# XHCI register map
File version: 1.2
xHCI host controller
Registers are read-write, no defined reset value unless marked. A register's access mark holds for its fields unless they carry their own. Offsets are from the block's base; lines under a group give offsets from that group; [hi:lo] are bit positions; {n}, {i} and the like mark numbered series; 'fields as' and 'values as' point back to an identical list; <NAME> marks a mode.

## Memory map
0x00000000 XHCI size 0x20

## XHCI
Base 0x00000000
0x00 CAPABILITY group
  0x00 CAPLENGTH 8-bit ro
  0x02 HCIVERSION 16-bit ro
    [15:0] VERSION
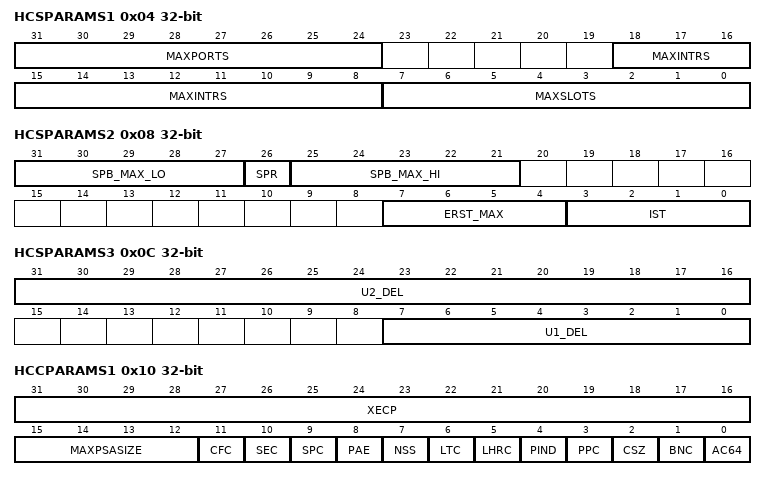
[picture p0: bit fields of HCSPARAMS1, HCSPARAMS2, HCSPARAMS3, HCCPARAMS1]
  0x04 HCSPARAMS1 ro
    [31:24] MAXPORTS, [18:8] MAXINTRS, [7:0] MAXSLOTS
  0x08 HCSPARAMS2 ro
    [31:27] SPB_MAX_LO, [26] SPR, [25:21] SPB_MAX_HI, [7:4] ERST_MAX, [3:0] IST
  0x0C HCSPARAMS3 ro
    [31:16] U2_DEL, [7:0] U1_DEL
  0x10 HCCPARAMS1 ro
    [31:16] XECP, [15:12] MAXPSASIZE, [11] CFC, [10] SEC, [9] SPC, [8] PAE, [7] NSS, [6] LTC, [5] LHRC, [4] PIND, [3] PPC, [2] CSZ, [1] BNC, [0] AC64
  0x14 DBOFF ro
    [31:2] OFFSET
  0x18 RTSOFF ro
    [31:5] OFFSET
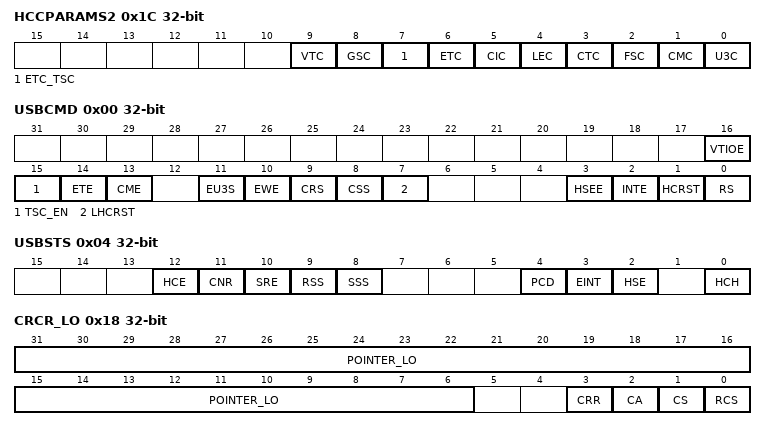
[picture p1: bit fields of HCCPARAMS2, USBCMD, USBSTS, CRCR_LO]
  0x1C HCCPARAMS2 ro
    [9] VTC, [8] GSC, [7] ETC_TSC, [6] ETC, [5] CIC, [4] LEC, [3] CTC, [2] FSC, [1] CMC, [0] U3C
0x00 OPERATIONAL group
  0x00 USBCMD
    [16] VTIOE, [15] TSC_EN, [14] ETE, [13] CME, [11] EU3S, [10] EWE, [9] CRS wo, [8] CSS wo, [7] LHCRST write-1-sets, [3] HSEE, [2] INTE, [1] HCRST write-1-sets, [0] RS
  0x04 USBSTS
    [12] HCE ro, [11] CNR ro, [10] SRE write-1-clears, [9] RSS ro, [8] SSS ro, [4] PCD write-1-clears, [3] EINT write-1-clears, [2] HSE write-1-clears, [0] HCH ro
  0x08 PAGESIZE ro
    [0] FOUR_KIB
  0x18 CRCR_LO
    [31:6] POINTER_LO wo, [3] CRR ro, [2] CA wo write-1-sets, [1] CS wo write-1-sets, [0] RCS wo
  0x1C CRCR_HI wo
    [31:0] POINTER_HI
  0x30 DCBAAP_LO
    [31:6] POINTER_LO
  0x34 DCBAAP_HI
    [31:0] POINTER_HI
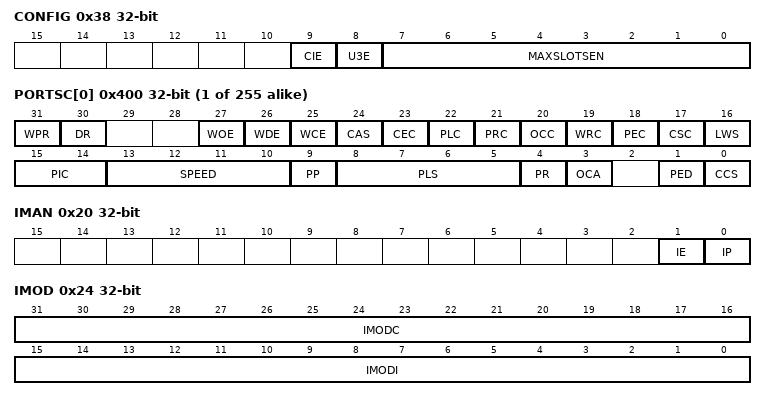
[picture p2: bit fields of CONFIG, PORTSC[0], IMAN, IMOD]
  0x38 CONFIG
    [9] CIE, [8] U3E, [7:0] MAXSLOTSEN
  {0x400+0x10*j} PORTSC[{j}] (j=0..254)
    [31] WPR wo write-1-sets
    [30] DR ro
    [27] WOE
    [26] WDE
    [25] WCE
    [24] CAS ro
    [23] CEC write-1-clears
    [22] PLC write-1-clears
    [21] PRC write-1-clears
    [20] OCC write-1-clears
    [19] WRC write-1-clears
    [18] PEC write-1-clears
    [17] CSC write-1-clears
    [16] LWS wo
    [15:14] PIC
    [13:10] SPEED ro
    [9] PP
    [8:5] PLS
      3=U3
    [4] PR write-1-sets
    [3] OCA ro
    [1] PED write-1-clears
    [0] CCS ro
0x00 RUNTIME group
  0x00 MFINDEX ro
    [13:0] INDEX
  0x20 IMAN
    [1] IE, [0] IP write-1-clears
  0x24 IMOD
    [31:16] IMODC, [15:0] IMODI
  0x28 ERSTSZ
    [15:0] SIZE
  0x30 ERSTBA_LO
    [31:6] ADDRESS_LO
  0x34 ERSTBA_HI
    [31:0] ADDRESS_HI
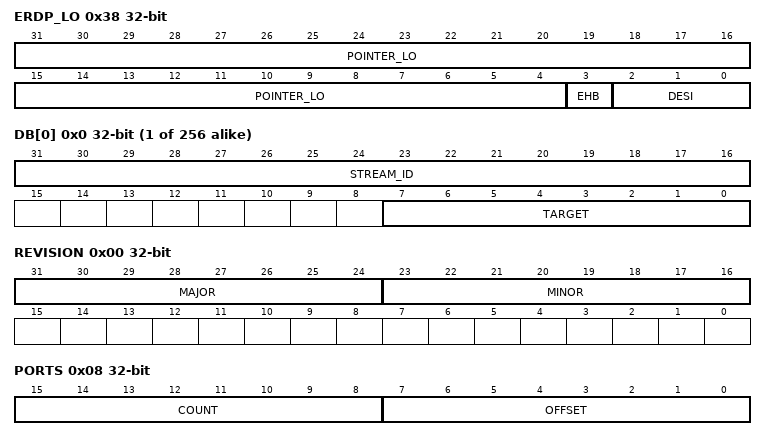
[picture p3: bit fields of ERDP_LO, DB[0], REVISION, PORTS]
  0x38 ERDP_LO
    [31:4] POINTER_LO, [3] EHB write-1-clears, [2:0] DESI
  0x3C ERDP_HI
    [31:0] POINTER_HI
0x00 DOORBELL group
  {0x0+4j} DB[{j}] (j=0..255) wo
    [31:16] STREAM_ID, [7:0] TARGET
0x00 LEGACY group
  0x02 BIOS_OWNED 8-bit
    [0] OWNED
  0x03 OS_OWNED 8-bit
    [0] OWNED
0x00 PROTOCOL[{i}] (i=0..7; step ?) group
  0x00 REVISION ro
    [31:24] MAJOR, [23:16] MINOR
  0x08 PORTS ro
    [15:8] COUNT, [7:0] OFFSET

## Notices in the file
Copyright (c) 2026, Stanislav Sedov <stas@deglitch.com>
SPDX-License-Identifier: BSD-2-Clause
